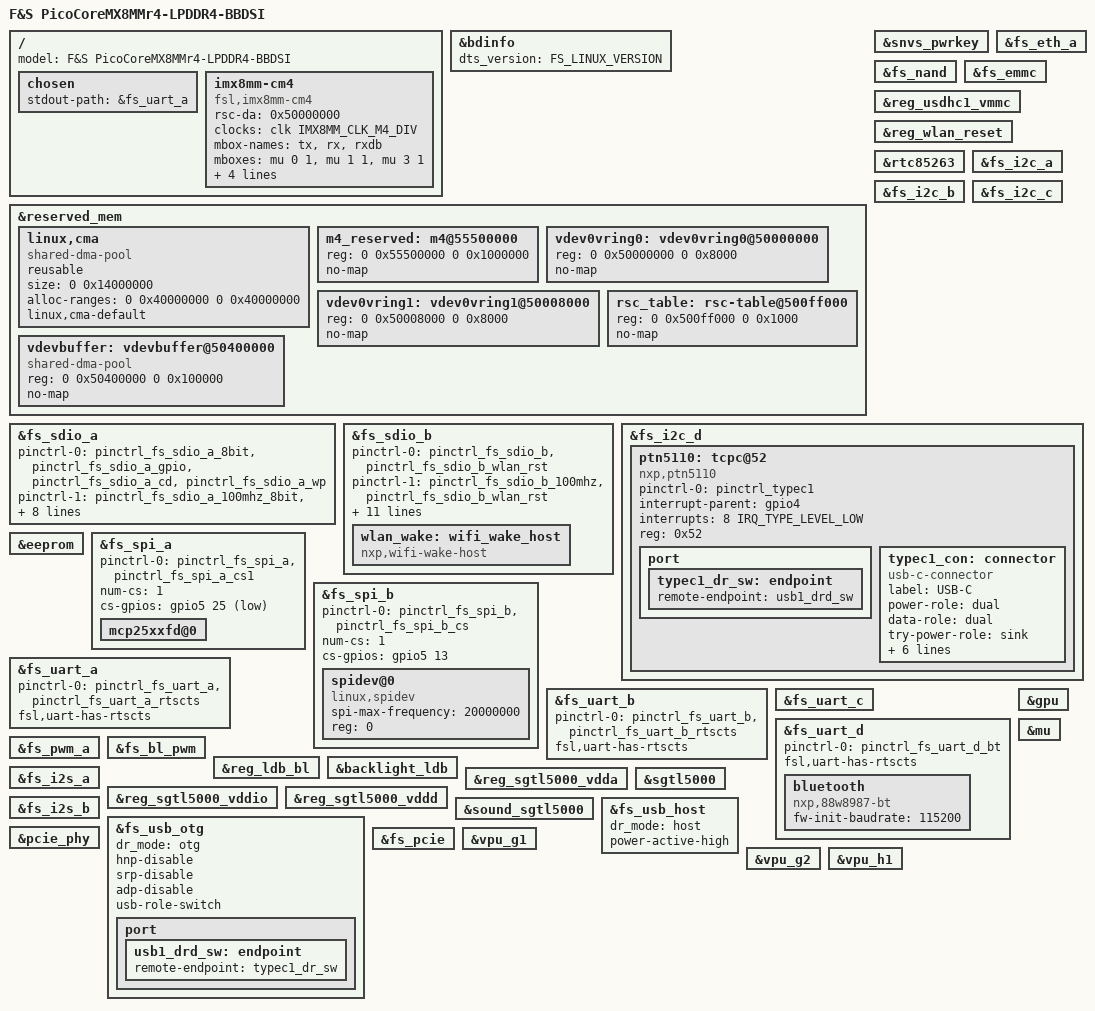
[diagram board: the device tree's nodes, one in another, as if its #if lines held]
/*
 * Copyright (C) 2026 F&S Elektronik Systeme GmbH
 *
 * This program is free software; you can redistribute it and/or modify
 * it under the terms of the GNU General Public License version 2 as
 * published by the Free Software Foundation.
 */

/dts-v1/;

/* Set board revision as 3-digit number, e.g. 110 for board rev. 1.10 */
#define CONFIG_PICOCOREMX8MM_BOARD_REVISION	100
/* Set baseboard revision as 3-digit number, e.g. 110 for board rev. 1.10 */
#define CONFIG_PICOCOREBBDSI_BOARD_REVISION	140

/* Activate this if you want to use the Cortex-M4 core */
//#define SUPPORT_M4

/* Display device-trees enables MIPI DSI */
/* MIPI DSI */
//#define CONFIG_PICOCOREMX8MM_MIPI_DSI

/*### UBoot deactivates on of the two boot medium NAND/eMMC */
/* On-board NAND */
#define CONFIG_PICOCOREMX8MM_NAND

/* On-board eMMC */
#define CONFIG_PICOCOREMX8MM_EMMC

/* Network */
#define CONFIG_PICOCOREMX8MM_ETH

/* WLAN/BLUETOOTH; either WLAN-only or combined WLAN/Bluetooth chip */
#define CONFIG_PICOCOREMX8MM_WLAN
#define CONFIG_PICOCOREMX8MM_BLUETOOTH

/* USB */
#define CONFIG_PICOCOREMX8MM_USB_OTG1
#define CONFIG_PICOCOREMX8MM_USB_HOST
#define CONFIG_PICOCOREMX8MM_USB_OTG1_USBC
/* USB Type-C ALERT signal is available on J2_77 on BBDSI baseboard since
 * Revision 1.40. Otherwise use polling with ~100ms
 */
#define CONFIG_PICOCOREMX8MM_USB_OTG1_USBC_ALERT

/* PCIe */
#define CONFIG_PICOCOREMX8MM_PCIE

/* I2C */
#define CONFIG_PICOCOREMX8MM_I2C_A
#define CONFIG_PICOCOREMX8MM_I2C_B
#define CONFIG_PICOCOREMX8MM_I2C_C
#define CONFIG_PICOCOREMX8MM_I2C_D

/* PWM and backlight brightness */
#define CONFIG_PICOCOREMX8MM_PWM_A
#define CONFIG_PICOCOREMX8MM_BL_CTRL

/* UART_A - UART1 */
#define CONFIG_PICOCOREMX8MM_UART_A
#define CONFIG_PICOCOREMX8MM_UART_A_RTSCTS

/* UART_B - UART2 */
#define CONFIG_PICOCOREMX8MM_UART_B
#define CONFIG_PICOCOREMX8MM_UART_B_RTSCTS

/* UART_C - UART4 */
#define CONFIG_PICOCOREMX8MM_UART_C

/* UART_D - UART3 */
#define CONFIG_PICOCOREMX8MM_UART_D

#define CONFIG_PICOCOREMX8MM_SPI_A
#define CONFIG_PICOCOREMX8MM_SPI_A_CAN_CONVERTER
//### TODO: implement QSPI support
#define CONFIG_PICOCOREMX8MM_SPI_B

/* EEPROM on I2C_D */
#define CONFIG_PICOCOREMX8MM_EEPROM

/* CAN-FD - optional */
//#define CONFIG_PICOCOREMX8MM_CAN_A

/* Audio */
#define CONFIG_PICOCOREMX8MM_SGTL5000_AUDIO
/* AUDIO_B is an example implementation and must be
 * modified.
 */
//#define CONFIG_PICOCOREMX8MM_AUDIO_B

/*
 * SD_A - External SD port with Card Detect (CD) and Write Protect (WP)
 * On picocoremx8mm SKIT: external port is Micro-SD card slot with CD but
 * without WP
 */
#define CONFIG_PICOCOREMX8MM_SD_A
#define CONFIG_PICOCOREMX8MM_SD_A_CD
//#define CONFIG_PICOCOREMX8MM_SD_A_WP
//#define CONFIG_PICOCOREMX8MM_SD_A_8_BIT

/*
 * SD_B - External SD port with Card Detect (CD) and Write Protect (WP)
 * only available if WLAN is not equipped.
 */
#define CONFIG_PICOCOREMX8MM_SD_B
#define CONFIG_PICOCOREMX8MM_SD_B_CD
#define CONFIG_PICOCOREMX8MM_SD_B_WP

/* Check for invalid CONFIG combinations */

/*
 * Exclude devices from Linux that are used by the Cortex-M4 FreeRTOS examples
 *
 * - UART_D: Debug Console for Cortex-M4
 * - I2C_A:  I2C Bus used in I2C examples
 * - I2C_D:  I2C Bus used by the Audio Codec in SAI examples
 * - SPI_B:  SPI_B is used for ECSPI examples
 * - SDMA1:  Gets removed at another Point, it is used by SPI_B and UART driver
 *           examples
 * - SPI_A:  SPI_A using SDMA1 but SDMA1 is excluded so also exclude SPI_A
 *
 * In addition the following pins are already predefined in FreeRTOS to be used
 * as arbitrary GPIOs. Please remove the comment of the appropriate line of
 * each device from which you use any signal in your own application.
 *
 * - AUDIO_3: GPT capture driver example uses one of its Pins
 */
#ifdef SUPPORT_M4
#undef CONFIG_PICOCOREMX8MM_UART_C
#undef CONFIG_PICOCOREMX8MM_I2C_A
#undef CONFIG_PICOCOREMX8MM_SPI_B
/* Only undef if using audio/sai examples */
//#undef CONFIG_PICOCOREMX8MM_I2C_D
//#undef CONFIG_PICOCOREMX8MM_SGTL5000_AUDIO
#endif

/* If WLAN is equipped, SD_B is not available */
#ifdef CONFIG_PICOCOREMX8MM_WLAN
#undef CONFIG_PICOCOREMX8MM_SD_B
#undef CONFIG_PICOCOREMX8MM_SD_B_CD
#undef CONFIG_PICOCOREMX8MM_SD_B_WP
#endif

/* Set different settings for corresponding baseboard revision */
#if CONFIG_PICOCOREBBDSI_BOARD_REVISION >= 130
#undef CONFIG_PICOCOREMX8MM_SPI_A_CAN_CONVERTER
#else
#undef CONFIG_PICOCOREMX8MM_USB_OTG1_USBC
#endif

#if !defined(CONFIG_PICOCOREMX8MM_USB_OTG1_USB) \
    || (CONFIG_PICOCOREBBDSI_BOARD_REVISION < 140)
#undef CONFIG_PICOCOREMX8MM_USB_OTG1_USBC_ALERT
#endif

#include "picocoremx8mmr4-lpddr4.dts"
#include <fsversion.h>

/ {
	model = "F&S PicoCoreMX8MMr4-LPDDR4-BBDSI";

	chosen {
		stdout-path = &fs_uart_a;
	};
};

&bdinfo {
	dts_version = FS_LINUX_VERSION;
};

&reserved_mem {
	linux,cma {
		compatible = "shared-dma-pool";
		reusable;
		size = <0 0x14000000>;
		alloc-ranges = <0 0x40000000 0 0x40000000>;
		linux,cma-default;
		//no-uboot-override;
	};
};

&snvs_pwrkey {
	status = "okay";
};

#ifdef CONFIG_PICOCOREMX8MM_ETH
&fs_eth_a {
	status = "okay";
};
#endif /* CONFIG_PICOCOREMX8MM_ETH */

#ifdef CONFIG_PICOCOREMX8MM_NAND
&fs_nand { status = "okay"; };
#endif /* CONFIG_PICOCOREMX8MM_NAND */

#ifdef CONFIG_PICOCOREMX8MM_EMMC
&fs_emmc { status = "okay"; };
#endif /* CONFIG_PICOCOREMX8MM_EMMC */

#ifdef CONFIG_PICOCOREMX8MM_SD_A
&reg_usdhc1_vmmc { status = "okay"; };

&fs_sdio_a {
	pinctrl-names = "default", "state_100mhz", "state_200mhz";
	pinctrl-0 = <&pinctrl_fs_sdio_a &pinctrl_fs_sdio_a_gpio
#ifdef CONFIG_PICOCOREMX8MM_SD_A_CD
		     &pinctrl_fs_sdio_a_cd
#endif
#ifdef CONFIG_PICOCOREMX8MM_SD_A_WP
		     &pinctrl_fs_sdio_a_wp
#endif
		    >;
	pinctrl-1 = <&pinctrl_fs_sdio_a_100mhz &pinctrl_fs_sdio_a_gpio
#ifdef CONFIG_PICOCOREMX8MM_SD_A_CD
		     &pinctrl_fs_sdio_a_cd
#endif
#ifdef CONFIG_PICOCOREMX8MM_SD_A_WP
		     &pinctrl_fs_sdio_a_wp
#endif
		    >;
	pinctrl-2 = <&pinctrl_fs_sdio_a_200mhz &pinctrl_fs_sdio_a_gpio
#ifdef CONFIG_PICOCOREMX8MM_SD_A_CD
		     &pinctrl_fs_sdio_a_cd
#endif
#ifdef CONFIG_PICOCOREMX8MM_SD_A_WP
		     &pinctrl_fs_sdio_a_wp
#endif
		    >;
#ifdef CONFIG_PICOCOREMX8MM_SD_A_8_BIT
	pinctrl-0 = <&pinctrl_fs_sdio_a_8bit &pinctrl_fs_sdio_a_gpio
#ifdef CONFIG_PICOCOREMX8MM_SD_A_CD
		     &pinctrl_fs_sdio_a_cd
#endif
#ifdef CONFIG_PICOCOREMX8MM_SD_A_WP
		     &pinctrl_fs_sdio_a_wp
#endif
		    >;
	pinctrl-1 = <&pinctrl_fs_sdio_a_100mhz_8bit &pinctrl_fs_sdio_a_gpio
#ifdef CONFIG_PICOCOREMX8MM_SD_A_CD
		     &pinctrl_fs_sdio_a_cd
#endif
#ifdef CONFIG_PICOCOREMX8MM_SD_A_WP
		     &pinctrl_fs_sdio_a_wp
#endif
		    >;
	pinctrl-2 = <&pinctrl_fs_sdio_a_200mhz_8bit &pinctrl_fs_sdio_a_gpio
#ifdef CONFIG_PICOCOREMX8MM_SD_A_CD
		     &pinctrl_fs_sdio_a_cd
#endif
#ifdef CONFIG_PICOCOREMX8MM_SD_A_WP
		     &pinctrl_fs_sdio_a_wp
#endif
		    >;
	bus-width = <8>;
#endif /* CONFIG_PICOCOREMX8MM_SD_A_8_BIT */
#ifdef CONFIG_PICOCOREMX8MM_SD_A_CD
	cd-gpios = <&gpio1 6 GPIO_ACTIVE_LOW>;
#else
	non-removable;
#endif
#ifdef CONFIG_PICOCOREMX8MM_SD_A_WP
	wp-gpios = <&gpio1 7 GPIO_ACTIVE_HIGH>;
#endif
	status = "okay";
};
#endif /* CONFIG_PICOCOREMX8MM_SD_A */

#ifdef CONFIG_PICOCOREMX8MM_SD_B
&fs_sdio_b {
	pinctrl-names = "default", "state_100mhz", "state_200mhz";
	pinctrl-0 = <&pinctrl_fs_sdio_b &pinctrl_fs_sdio_b_rst
#ifdef CONFIG_PICOCOREMX8MM_SD_B_CD
		     &pinctrl_fs_sdio_b_cd
#endif
#ifdef CONFIG_PICOCOREMX8MM_SD_B_WP
		     &pinctrl_fs_sdio_b_wp
#endif
		    >;
	pinctrl-1 = <&pinctrl_fs_sdio_b_100mhz &pinctrl_fs_sdio_b_rst
#ifdef CONFIG_PICOCOREMX8MM_SD_B_CD
		     &pinctrl_fs_sdio_b_cd
#endif
#ifdef CONFIG_PICOCOREMX8MM_SD_B_WP
		     &pinctrl_fs_sdio_b_wp
#endif
		    >;
	pinctrl-2 = <&pinctrl_fs_sdio_b_200mhz &pinctrl_fs_sdio_b_rst
#ifdef CONFIG_PICOCOREMX8MM_SD_B_CD
		     &pinctrl_fs_sdio_b_cd
#endif
#ifdef CONFIG_PICOCOREMX8MM_SD_B_WP
		     &pinctrl_fs_sdio_b_wp
#endif
		    >;
#ifdef CONFIG_PICOCOREMX8MM_SD_B_CD
	cd-gpios = <&gpio2 12 GPIO_ACTIVE_LOW>;
#else
	non-removable;
#endif
#ifdef CONFIG_PICOCOREMX8MM_SD_B_WP
	wp-gpios = <&gpio2 20 GPIO_ACTIVE_HIGH>;
#endif
	status = "okay";
};
#endif /* CONFIG_PICOCOREMX8MM_SD_B */

#ifdef CONFIG_PICOCOREMX8MM_WLAN
&reg_wlan_reset { status = "okay"; };

&fs_sdio_b {
	pinctrl-names = "default", "state_100mhz", "state_200mhz";
	pinctrl-0 = <&pinctrl_fs_sdio_b &pinctrl_fs_sdio_b_wlan_rst>;
	pinctrl-1 = <&pinctrl_fs_sdio_b_100mhz &pinctrl_fs_sdio_b_wlan_rst>;
	pinctrl-2 = <&pinctrl_fs_sdio_b_200mhz &pinctrl_fs_sdio_b_wlan_rst>;
	non-removable;
	vmmc-supply = <&reg_vref_3v3>;
	vqmmc-supply = <&reg_vref_1v8>;
	enable-sdio-wakeup;
	cap-power-off-card;
	fsl,sdio-async-interrupt-enabled;
	mmc-pwrseq = <&usdhc2_pwrseq>;

	status = "okay";

	wlan_wake: wifi_wake_host {
		compatible = "nxp,wifi-wake-host";
	};
};
#endif /* CONFIG_PICOCOREMX8MM_WLAN */

/* only one RTC chip is ever populated - uncertain which one is the actual
 * default population on this board, verify against the schematic and
 * disable/switch below if it turns out to be the pcf85063 instead */
&rtc85263 {
	status = "okay";
};

#ifdef CONFIG_PICOCOREMX8MM_I2C_A
&fs_i2c_a { status = "okay"; };
#endif /* CONFIG_PICOCOREMX8MM_I2C_A */

#ifdef CONFIG_PICOCOREMX8MM_I2C_B
&fs_i2c_b { status = "okay"; };
#endif /* CONFIG_PICOCOREMX8MM_I2C_B */

#ifdef CONFIG_PICOCOREMX8MM_I2C_C
&fs_i2c_c { status = "okay"; };
#endif /* CONFIG_PICOCOREMX8MM_I2C_C */

#ifdef CONFIG_PICOCOREMX8MM_I2C_D
&fs_i2c_d {

#ifdef CONFIG_PICOCOREMX8MM_USB_OTG1_USBC
	/* USB-C */
	ptn5110: tcpc@52 {
		compatible = "nxp,ptn5110";
#ifdef CONFIG_PICOCOREMX8MM_USB_OTG1_USBC_ALERT
		pinctrl-names = "default";
		pinctrl-0 = <&pinctrl_typec1>;
		interrupt-parent = <&gpio4>;
		interrupts = <8 IRQ_TYPE_LEVEL_LOW>;
#endif
		reg = <0x52>;
		status = "okay";

		port {
			typec1_dr_sw: endpoint {
				remote-endpoint = <&usb1_drd_sw>;
			};
		};

		typec1_con: connector {
			compatible = "usb-c-connector";
			label = "USB-C";
			power-role = "dual";
			data-role = "dual";
			try-power-role = "sink";
			source-pdos = <PDO_FIXED(5000, 3000, PDO_FIXED_USB_COMM)>;
			sink-pdos = <PDO_FIXED(5000, 3000, PDO_FIXED_USB_COMM)
				     PDO_VAR(5000, 20000, 3000)>;
			op-sink-microwatt = <15000000>;
			self-powered;
		};
	};
#endif /* CONFIG_PICOCOREMX8MM_USB_OTG1_USBC */
};

#ifdef CONFIG_PICOCOREMX8MM_EEPROM
&eeprom { status = "okay"; };
#endif

#endif /* CONFIG_PICOCOREMX8MM_I2C_D */

#ifdef CONFIG_PICOCOREMX8MM_SPI_A
&fs_spi_a {
	pinctrl-0 = <&pinctrl_fs_spi_a>, <&pinctrl_fs_spi_a_cs1>;
	num-cs = <1>;
	cs-gpios = <&gpio5 25 GPIO_ACTIVE_LOW>;
	status = "okay";
#ifdef CONFIG_PICOCOREMX8MM_CAN_A
	mcp25xxfd@0 {
		status = "okay";
	};
#else
	spidev@0 {
		compatible = "linux,spidev";
		spi-max-frequency = <20000000>;
		reg = <0>;
		status = "okay";
	};
#endif /* CONFIG_PICOCOREMX8MM_CAN_A */
};
#endif /* CONFIG_PICOCOREMX8MM_SPI_A */


#ifdef CONFIG_PICOCOREMX8MM_SPI_B
&fs_spi_b {
	pinctrl-0 = <&pinctrl_fs_spi_b>, <&pinctrl_fs_spi_b_cs>;
	num-cs = <1>;
	cs-gpios = <&gpio5 13 0>;
	status = "okay";

	spidev@0 {
		compatible = "linux,spidev";
		spi-max-frequency = <20000000>;
		reg = <0>;
		status = "okay";
	};
};
#endif /* CONFIG_PICOCOREMX8MM_SPI_B */

#ifdef CONFIG_PICOCOREMX8MM_UART_A
&fs_uart_a { /* console */
#ifdef CONFIG_PICOCOREMX8MM_UART_A_RTSCTS
	pinctrl-0 = <&pinctrl_fs_uart_a>, <&pinctrl_fs_uart_a_rtscts>;
	fsl,uart-has-rtscts;
#endif /* CONFIG_PICOCOREMX8MM_UART_A_RTSCTS */
	status = "okay";
};
#endif /* CONFIG_PICOCOREMX8MM_UART_A */

#ifdef CONFIG_PICOCOREMX8MM_UART_B
&fs_uart_b {
#ifdef CONFIG_PICOCOREMX8MM_UART_B_RTSCTS
	pinctrl-0 = <&pinctrl_fs_uart_b>, <&pinctrl_fs_uart_b_rtscts>;
	fsl,uart-has-rtscts;
#endif /* CONFIG_PICOCOREMX8MM_UART_B_RTSCTS */
	status = "okay";
};
#endif /* CONFIG_PICOCOREMX8MM_UART_B */

#ifdef CONFIG_PICOCOREMX8MM_UART_C
&fs_uart_c { status = "okay"; };
#endif /* CONFIG_PICOCOREMX8MM_UART_C */

#ifdef CONFIG_PICOCOREMX8MM_UART_D
&fs_uart_d {
#ifdef CONFIG_PICOCOREMX8MM_BLUETOOTH

	pinctrl-0 = <&pinctrl_fs_uart_d_bt>;
	fsl,uart-has-rtscts;
	status = "okay";

	bluetooth: bluetooth {
		compatible = "nxp,88w8987-bt";
		fw-init-baudrate = <115200>;
	};
#else
	status = "okay";
#endif /* CONFIG_PICOCOREMX8MM_BLUETOOTH */
};
#endif /* CONFIG_PICOCOREMX8MM_UART_D */

#ifdef CONFIG_PICOCOREMX8MM_PWM_A
&fs_pwm_a { status = "okay"; };
#endif /* CONFIG_PICOCOREMX8MM_PWM_A */

#ifdef CONFIG_PICOCOREMX8MM_BL_CTRL
&fs_bl_pwm { status = "okay"; };
&reg_ldb_bl { status = "okay"; };
&backlight_ldb { status = "okay"; };
#endif /* CONFIG_PICOCOREMX8MM_BL_CTRL */

#ifdef CONFIG_PICOCOREMX8MM_SGTL5000_AUDIO
&fs_i2s_a { status = "okay"; };
&reg_sgtl5000_vdda { status = "okay"; };
&reg_sgtl5000_vddio { status = "okay"; };
&reg_sgtl5000_vddd { status = "okay"; };
&sound_sgtl5000 { status = "okay"; };
&sgtl5000 { status = "okay"; };
#endif /* CONFIG_PICOCOREMX8MM_SGTL5000_AUDIO */

#ifdef CONFIG_PICOCOREMX8MM_AUDIO_B
&fs_i2s_b { status = "okay"; };
#endif /* CONFIG_PICOCOREMX8MM_AUDIO_B */

#ifdef CONFIG_PICOCOREMX8MM_USB_OTG1
&fs_usb_otg {
	dr_mode = "otg";
	status = "okay";
#ifdef CONFIG_PICOCOREMX8MM_USB_OTG1_USBC
	hnp-disable;
	srp-disable;
	adp-disable;
	usb-role-switch;

	port {
		usb1_drd_sw: endpoint {
			remote-endpoint = <&typec1_dr_sw>;
		};
	};
#endif /* CONFIG_PICOCOREMX8MM_USB_OTG1_USBC */
};
#endif /* CONFIG_PICOCOREMX8MM_USB_OTG1 */

#ifdef CONFIG_PICOCOREMX8MM_USB_HOST
&fs_usb_host {
	dr_mode = "host";
	power-active-high;
	status = "okay";
};
#endif

#ifdef CONFIG_PICOCOREMX8MM_PCIE
&pcie_phy { status = "okay"; };
&fs_pcie { status = "okay"; };
#endif /* CONFIG_PICOCOREMX8MM_PCIE */

/* no CONFIG_PICOCOREMX8MM_GPU/_VPU define exists for this module - the SoC
 * accelerators were always enabled unconditionally before the hardening
 * rework, keep that behaviour here. */
&gpu { status = "okay"; };
&vpu_g1 { status = "okay"; };
&vpu_g2 { status = "okay"; };
&vpu_h1 { status = "okay"; };

#ifdef SUPPORT_M4
&mu { status = "okay"; };

/{
	imx8mm-cm4 {
		compatible = "fsl,imx8mm-cm4";
		rsc-da = <0x50000000>;
		clocks = <&clk IMX8MM_CLK_M4_DIV>;
		mbox-names = "tx", "rx", "rxdb";
		mboxes = <&mu 0 1
			  &mu 1 1
			  &mu 3 1>;
		memory-region = <&vdev0vring0>, <&vdev0vring1>, <&vdevbuffer>, <&rsc_table>, <&m4_reserved>;
		syscon = <&src>;
		fsl,startup-delay-ms = <500>;
	};
};

&reserved_mem {
	m4_reserved: m4@55500000 {
		reg = <0 0x55500000 0 0x1000000>;
		no-map;
	};

	vdev0vring0: vdev0vring0@50000000 {
		reg = <0 0x50000000 0 0x8000>;
		no-map;
	};

	vdev0vring1: vdev0vring1@50008000 {
		reg = <0 0x50008000 0 0x8000>;
		no-map;
	};

	rsc_table: rsc-table@500ff000 {
		reg = <0 0x500ff000 0 0x1000>;
		no-map;
	};

	vdevbuffer: vdevbuffer@50400000 {
		compatible = "shared-dma-pool";
		reg = <0 0x50400000 0 0x100000>;
		no-map;
	};
};
#endif /* SUPPORT_M4 */
